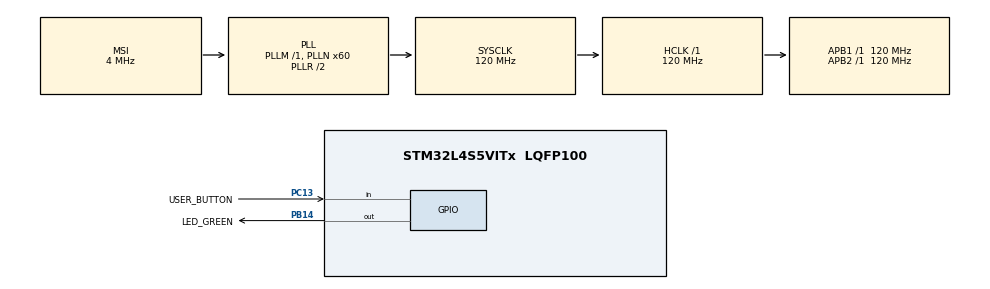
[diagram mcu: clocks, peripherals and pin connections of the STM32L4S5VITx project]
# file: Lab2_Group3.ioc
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ADC1.Channel-1\#ChannelRegularConversion=ADC_CHANNEL_TEMPSENSOR
ADC1.Channel-2\#ChannelRegularConversion=ADC_CHANNEL_TEMPSENSOR
ADC1.ContinuousConvMode=ENABLE
ADC1.EOCSelection=ADC_EOC_SEQ_CONV
ADC1.NbrOfConversion=2
ADC1.NbrOfConversionFlag=1
ADC1.OffsetNumber-1\#ChannelRegularConversion=ADC_OFFSET_NONE
ADC1.OffsetNumber-2\#ChannelRegularConversion=ADC_OFFSET_NONE
ADC1.Rank-1\#ChannelRegularConversion=1
ADC1.Rank-2\#ChannelRegularConversion=2
ADC1.SamplingTime-1\#ChannelRegularConversion=ADC_SAMPLETIME_2CYCLES_5
ADC1.SamplingTime-2\#ChannelRegularConversion=ADC_SAMPLETIME_2CYCLES_5
ADC1.master=1
Mcu.Family=STM32L4
Mcu.Name=STM32L4S5VITx
Mcu.Package=LQFP100
NVIC.ADC1_IRQn=true\:0\:0\:false\:false\:true\:true\:true
NVIC.PriorityGroup=NVIC_PRIORITYGROUP_4
PB14.GPIO_Label=LED_GREEN
PB14.Signal=GPIO_Output
PC13.GPIO_Label=USER_BUTTON
PC13.Signal=GPIO_Input
ProjectManager.HeapSize=0x200
ProjectManager.StackSize=0x400
ProjectManager.TargetToolchain=STM32CubeIDE
RCC.ADCFreq_Value=48000000
RCC.AHBFreq_Value=120000000
RCC.APB1Freq_Value=120000000
RCC.APB1TimFreq_Value=120000000
RCC.APB2Freq_Value=120000000
RCC.APB2TimFreq_Value=120000000
RCC.CortexFreq_Value=120000000
RCC.HCLKFreq_Value=120000000
RCC.HSE_VALUE=8000000
RCC.HSI48_VALUE=48000000
RCC.HSI_VALUE=16000000
RCC.LSE_VALUE=32768
RCC.MSI_VALUE=4000000
RCC.PLLN=60
RCC.PLLSAI1N=24
RCC.SYSCLKFreq_VALUE=120000000
RCC.SYSCLKSource=RCC_SYSCLKSOURCE_PLLCLK
RCC.USBFreq_Value=48000000
RCC.VCOOutputFreq_Value=240000000
VP_ADC1_TempSens_Input.Mode=IN-TempSens
VP_ADC1_Vref_Input.Mode=IN-Vrefint
board=B-L4S5I-IOT01A

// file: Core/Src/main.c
/* USER CODE BEGIN Header */
/**
  ******************************************************************************
  * @file           : main.c
  * @brief          : Main program body
  ******************************************************************************
  * @attention
  *
  * <h2><center>&copy; Copyright (c) 2021 STMicroelectronics.
  * All rights reserved.</center></h2>
  *
  * This software component is licensed by ST under BSD 3-Clause license,
  * the "License"; You may not use this file except in compliance with the
  * License. You may obtain a copy of the License at:
  *                        opensource.org/licenses/BSD-3-Clause
  *
  ******************************************************************************
  */
/* USER CODE END Header */
#include "main.h"

ADC_HandleTypeDef hadc1;

void SystemClock_Config(void);
static void MX_GPIO_Init(void);
static void MX_ADC1_Init(void);

/* USER CODE BEGIN 0 */
//#define START_WITH_TEMP 1
uint32_t fromADC;
float vref_measured = 3300.0;
float vref_HALchecker;
float tempCelcius_measured;
float tempCelcius_HALchecker;
/* USER CODE END 0 */

int main(void)
{

  /* MCU Configuration--------------------------------------------------------*/

  /* Reset of all peripherals, Initializes the Flash interface and the Systick. */
  HAL_Init();

  /* Configure the system clock */
  SystemClock_Config();

  /* Initialize all configured peripherals */
  MX_GPIO_Init();
  MX_ADC1_Init();
  /* USER CODE BEGIN 2 */
  HAL_ADCEx_Calibration_Start(&hadc1, ADC_SINGLE_ENDED); // calibrate for better Vref
  // T = tempCoef * (TS_DATA  TS_CAL1) + 30
  // where tempCoef = (tempCalT2 - tempCalT1)/ (tempCalV2 - tempCalV1) doesn't change
  // so it only has to be calculated once before the while loop
  float tempCalV1 = (float) (*TEMPSENSOR_CAL1_ADDR);
  float tempCalV2 = (float) (*TEMPSENSOR_CAL2_ADDR);
  float tempCoef = (float)(TEMPSENSOR_CAL2_TEMP-TEMPSENSOR_CAL1_TEMP)/ (tempCalV2 - tempCalV1);
  ADC_ChannelConfTypeDef sConfig = {0};
  uint16_t  VREFINT_CAL = *VREFINT_CAL_ADDR;
  /* USER CODE END 2 */

  /* Infinite loop */
  /* USER CODE BEGIN WHILE */
  if (HAL_ADC_Start(&hadc1) != HAL_OK) { // ensure everything is enabled, state bitfield is clean, etc.
	  Error_Handler();
  }
  while (1)
  {
	  if(!HAL_GPIO_ReadPin(USER_BUTTON_GPIO_Port, USER_BUTTON_Pin)){ // RESET=0U
		  HAL_Delay(1);
		  if(HAL_GPIO_ReadPin(USER_BUTTON_GPIO_Port, USER_BUTTON_Pin)){ // SET=1U, a rising edge is detected
		  	HAL_GPIO_TogglePin(LED_GREEN_GPIO_Port, LED_GREEN_Pin); // toggle LED mode
		  }
	  }

		if(HAL_ADC_PollForConversion(&hadc1, 100) == HAL_OK){ // Wait for regular group conversion to be completed
				  fromADC = HAL_ADC_GetValue(&hadc1);// fetch reading from ADC data register as an uint32_t
				  // VREF+ = VREF+_Charac  * VREFINT_CAL / VREFINT_DATA
				  vref_measured = 3000.0 * (float)VREFINT_CAL / (float)fromADC;
				  // the auto generated helper macro for sanity check
				  vref_HALchecker = __LL_ADC_CALC_VREFANALOG_VOLTAGE(fromADC, ADC_RESOLUTION_12B);
		}

	  if(HAL_ADC_PollForConversion(&hadc1, 100) == HAL_OK){ // Wait for regular group conversion to be completed
			  fromADC = HAL_ADC_GetValue(&hadc1); // fetch reading from ADC data register as an uint32_t
	    	  // the auto generated helper macro for sanity check
			  tempCelcius_HALchecker = __HAL_ADC_CALC_TEMPERATURE(vref_measured, fromADC, ADC_RESOLUTION_12B);
	    	  // T = tempCoef * (TS_DATA �? TS_CAL1) + 30, where TSCAL data are acquired at VREF+char=3.0 V
	    	  // Our Vref is not 3.0V, need to scale the readout in the formula by TSDATA*(VREF+actual/VREF+char)
	    	  tempCelcius_measured = 30.0 + tempCoef *
	    			  ((float)fromADC * vref_measured / 3000.0 - tempCalV1);
		  }

    /* USER CODE END WHILE */

    /* USER CODE BEGIN 3 */
  }
  if (HAL_ADC_Stop(&hadc1) != HAL_OK) {
	  Error_Handler();
  }
  /* USER CODE END 3 */
}

void SystemClock_Config(void)
{
  RCC_OscInitTypeDef RCC_OscInitStruct = {0};
  RCC_ClkInitTypeDef RCC_ClkInitStruct = {0};
  RCC_PeriphCLKInitTypeDef PeriphClkInit = {0};

  /** Configure the main internal regulator output voltage
  */
  if (HAL_PWREx_ControlVoltageScaling(PWR_REGULATOR_VOLTAGE_SCALE1_BOOST) != HAL_OK)
  {
    Error_Handler();
  }
  /** Initializes the RCC Oscillators according to the specified parameters
  * in the RCC_OscInitTypeDef structure.
  */
  RCC_OscInitStruct.OscillatorType = RCC_OSCILLATORTYPE_MSI;
  RCC_OscInitStruct.MSIState = RCC_MSI_ON;
  RCC_OscInitStruct.MSICalibrationValue = 0;
  RCC_OscInitStruct.MSIClockRange = RCC_MSIRANGE_6;
  RCC_OscInitStruct.PLL.PLLState = RCC_PLL_ON;
  RCC_OscInitStruct.PLL.PLLSource = RCC_PLLSOURCE_MSI;
  RCC_OscInitStruct.PLL.PLLM = 1;
  RCC_OscInitStruct.PLL.PLLN = 60;
  RCC_OscInitStruct.PLL.PLLP = RCC_PLLP_DIV2;
  RCC_OscInitStruct.PLL.PLLQ = RCC_PLLQ_DIV2;
  RCC_OscInitStruct.PLL.PLLR = RCC_PLLR_DIV2;
  if (HAL_RCC_OscConfig(&RCC_OscInitStruct) != HAL_OK)
  {
    Error_Handler();
  }
  /** Initializes the CPU, AHB and APB buses clocks
  */
  RCC_ClkInitStruct.ClockType = RCC_CLOCKTYPE_HCLK|RCC_CLOCKTYPE_SYSCLK
                              |RCC_CLOCKTYPE_PCLK1|RCC_CLOCKTYPE_PCLK2;
  RCC_ClkInitStruct.SYSCLKSource = RCC_SYSCLKSOURCE_PLLCLK;
  RCC_ClkInitStruct.AHBCLKDivider = RCC_SYSCLK_DIV1;
  RCC_ClkInitStruct.APB1CLKDivider = RCC_HCLK_DIV1;
  RCC_ClkInitStruct.APB2CLKDivider = RCC_HCLK_DIV1;

  if (HAL_RCC_ClockConfig(&RCC_ClkInitStruct, FLASH_LATENCY_5) != HAL_OK)
  {
    Error_Handler();
  }
  PeriphClkInit.PeriphClockSelection = RCC_PERIPHCLK_ADC;
  PeriphClkInit.AdcClockSelection = RCC_ADCCLKSOURCE_PLLSAI1;
  PeriphClkInit.PLLSAI1.PLLSAI1Source = RCC_PLLSOURCE_MSI;
  PeriphClkInit.PLLSAI1.PLLSAI1M = 1;
  PeriphClkInit.PLLSAI1.PLLSAI1N = 24;
  PeriphClkInit.PLLSAI1.PLLSAI1P = RCC_PLLP_DIV2;
  PeriphClkInit.PLLSAI1.PLLSAI1Q = RCC_PLLQ_DIV2;
  PeriphClkInit.PLLSAI1.PLLSAI1R = RCC_PLLR_DIV2;
  PeriphClkInit.PLLSAI1.PLLSAI1ClockOut = RCC_PLLSAI1_ADC1CLK;
  if (HAL_RCCEx_PeriphCLKConfig(&PeriphClkInit) != HAL_OK)
  {
    Error_Handler();
  }
}

static void MX_ADC1_Init(void)
{

  ADC_ChannelConfTypeDef sConfig = {0};

  /** Common config
  */
  hadc1.Instance = ADC1;
  hadc1.Init.ClockPrescaler = ADC_CLOCK_ASYNC_DIV1;
  hadc1.Init.Resolution = ADC_RESOLUTION_12B;
  hadc1.Init.DataAlign = ADC_DATAALIGN_RIGHT;
  hadc1.Init.ScanConvMode = ADC_SCAN_DISABLE;
  hadc1.Init.EOCSelection = ADC_EOC_SEQ_CONV;
  hadc1.Init.LowPowerAutoWait = DISABLE;
  hadc1.Init.ContinuousConvMode = ENABLE;
  hadc1.Init.NbrOfConversion = 2;
  hadc1.Init.DiscontinuousConvMode = DISABLE;
  hadc1.Init.ExternalTrigConv = ADC_SOFTWARE_START;
  hadc1.Init.ExternalTrigConvEdge = ADC_EXTERNALTRIGCONVEDGE_NONE;
  hadc1.Init.DMAContinuousRequests = DISABLE;
  hadc1.Init.Overrun = ADC_OVR_DATA_PRESERVED;
  hadc1.Init.OversamplingMode = DISABLE;
  if (HAL_ADC_Init(&hadc1) != HAL_OK)
  {
    Error_Handler();
  }
  /** Configure Regular Channel
  */
  sConfig.Channel = ADC_CHANNEL_TEMPSENSOR;
  sConfig.Rank = ADC_REGULAR_RANK_1;
  sConfig.SamplingTime = ADC_SAMPLETIME_640CYCLES_5;
  sConfig.SingleDiff = ADC_SINGLE_ENDED;
  sConfig.OffsetNumber = ADC_OFFSET_NONE;
  sConfig.Offset = 0;
  if (HAL_ADC_ConfigChannel(&hadc1, &sConfig) != HAL_OK)
  {
    Error_Handler();
  }
  /** Configure Regular Channel
  */

}

static void MX_GPIO_Init(void)
{
  GPIO_InitTypeDef GPIO_InitStruct = {0};

  /* GPIO Ports Clock Enable */
  __HAL_RCC_GPIOC_CLK_ENABLE();
  __HAL_RCC_GPIOB_CLK_ENABLE();

  /*Configure GPIO pin Output Level */
  HAL_GPIO_WritePin(LED_GREEN_GPIO_Port, LED_GREEN_Pin, GPIO_PIN_RESET);

  /*Configure GPIO pin : USER_BUTTON_Pin */
  GPIO_InitStruct.Pin = USER_BUTTON_Pin;
  GPIO_InitStruct.Mode = GPIO_MODE_INPUT;
  GPIO_InitStruct.Pull = GPIO_NOPULL;
  HAL_GPIO_Init(USER_BUTTON_GPIO_Port, &GPIO_InitStruct);

  /*Configure GPIO pin : LED_GREEN_Pin */
  GPIO_InitStruct.Pin = LED_GREEN_Pin;
  GPIO_InitStruct.Mode = GPIO_MODE_OUTPUT_PP;
  GPIO_InitStruct.Pull = GPIO_NOPULL;
  GPIO_InitStruct.Speed = GPIO_SPEED_FREQ_LOW;
  HAL_GPIO_Init(LED_GREEN_GPIO_Port, &GPIO_InitStruct);

}

void Error_Handler(void)
{
  __disable_irq();
  while (1)
  {
  }
}

/************************ (C) COPYRIGHT STMicroelectronics *****END OF FILE****/
